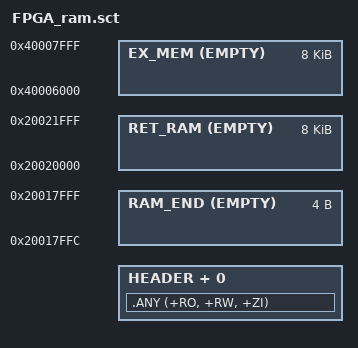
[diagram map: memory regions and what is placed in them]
; *************************************************************
; *** Scatter-Loading Description File generated by uVision ***
; *************************************************************

SOC 0x20000000 0x18000  ; 96KB
{
    STARTUP + 0
    {
        *(VECTOR_TABLE, +First)
    }

    HEADER + 0 FIXED                ;should always start from offset 0xC0
    {
        *(IMAGE_HEADER, +First)
    }

;    BLE_JUMP_TABLE 0x20000200 FIXED 0x400
;    {
;        .ANY (jump_table_mem_area)
;    }

    IMAGE_RO + 0
    {
        *(InRoot$$Sections)
        * (+RO)
    }

    IMAGE_RW + 0
    {
        ;*(RO_IN_SYS_RAM)
        ;*(RW_IN_SYS_RAM)
        ;clock.o (+RO, +RW, +ZI)
        * (+RW)
    }

    IMAGE_ZI + 0
    {
        ;*(ZI_IN_SYS_RAM)
        * (+ZI)
    }

    RAM_START + 0
    {
        .ANY (+RO, +RW, +ZI)
    }

    RAM_END 0x20018000 EMPTY -0x4
    {

    }

    RET_RAM 0x20020000 EMPTY 0x2000 ; Retention memory
    {

    }

    EX_MEM 0x40006000 EMPTY 0x2000 ; Exchange memory
    {

    }
}

